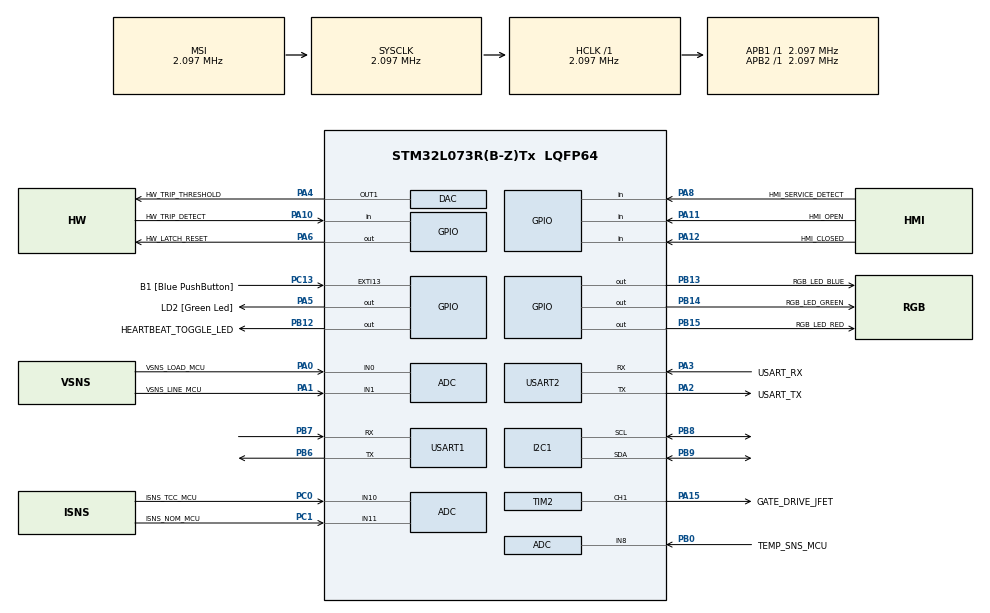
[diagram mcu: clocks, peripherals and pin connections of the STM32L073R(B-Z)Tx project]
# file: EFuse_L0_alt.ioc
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ADC.EOCSelection=ADC_EOC_SEQ_CONV
ADC.SamplingTime=ADC_SAMPLETIME_160CYCLES_5
I2C1.Timing=0x00000608
Mcu.Family=STM32L0
Mcu.Name=STM32L073R(B-Z)Tx
Mcu.Package=LQFP64
PA0.GPIO_Label=VSNS_LOAD_MCU
PA0.Mode=IN0
PA0.Signal=ADC_IN0
PA1.GPIO_Label=VSNS_LINE_MCU
PA1.Mode=IN1
PA1.Signal=ADC_IN1
PA10.GPIO_Label=HW_TRIP_DETECT
PA10.Signal=GPIO_Input
PA11.GPIO_Label=HMI_OPEN
PA11.Signal=GPIO_Input
PA12.GPIO_Label=HMI_CLOSED
PA12.Signal=GPIO_Input
PA13.GPIO_Label=TMS
PA13.Mode=Serial_Wire
PA13.Signal=SYS_SWDIO
PA14.GPIO_Label=TCK
PA14.Mode=Serial_Wire
PA14.Signal=SYS_SWCLK
PA15.GPIO_Label=GATE_DRIVE_JFET
PA15.Signal=S_TIM2_CH1
PA2.GPIO_Label=USART_TX
PA2.Mode=Asynchronous
PA2.Signal=USART2_TX
PA3.GPIO_Label=USART_RX
PA3.Mode=Asynchronous
PA3.Signal=USART2_RX
PA4.GPIO_Label=HW_TRIP_THRESHOLD
PA4.Signal=COMP_DAC1_group
PA5.GPIO_Label=LD2 [Green Led]
PA5.Signal=GPIO_Output
PA6.GPIO_Label=HW_LATCH_RESET
PA6.Signal=GPIO_Output
PA8.GPIO_Label=HMI_SERVICE_DETECT
PA8.Signal=GPIO_Input
PB0.GPIO_Label=TEMP_SNS_MCU
PB0.Mode=IN8
PB0.Signal=ADC_IN8
PB12.GPIO_Label=HEARTBEAT_TOGGLE_LED
PB12.Signal=GPIO_Output
PB13.GPIO_Label=RGB_LED_BLUE
PB13.Signal=GPIO_Output
PB14.GPIO_Label=RGB_LED_GREEN
PB14.Signal=GPIO_Output
PB15.GPIO_Label=RGB_LED_RED
PB15.Signal=GPIO_Output
PB6.Mode=Asynchronous
PB6.Signal=USART1_TX
PB7.Mode=Asynchronous
PB7.Signal=USART1_RX
PB8.Mode=I2C
PB8.Signal=I2C1_SCL
PB9.Mode=I2C
PB9.Signal=I2C1_SDA
PC0.GPIO_Label=ISNS_TCC_MCU
PC0.Mode=IN10
PC0.Signal=ADC_IN10
PC1.GPIO_Label=ISNS_NOM_MCU
PC1.Mode=IN11
PC1.Signal=ADC_IN11
PC13.GPIO_Label=B1 [Blue PushButton]
PC13.GPIO_ModeDefaultEXTI=GPIO_MODE_IT_FALLING
PC13.Signal=GPXTI13
PC14-OSC32_IN.Mode=LSE-External-Oscillator
PC14-OSC32_IN.Signal=RCC_OSC32_IN
PC15-OSC32_OUT.Mode=LSE-External-Oscillator
PC15-OSC32_OUT.Signal=RCC_OSC32_OUT
PH0-OSC_IN.GPIO_Label=MCO
PH0-OSC_IN.Mode=HSE-External-Clock-Source
PH0-OSC_IN.Signal=RCC_OSC_IN
ProjectManager.HeapSize=0x200
ProjectManager.StackSize=0x400
ProjectManager.TargetToolchain=CMake
RCC.AHBFreq_Value=2097000
RCC.APB1Freq_Value=2097000
RCC.APB1TimFreq_Value=2097000
RCC.APB2Freq_Value=2097000
RCC.APB2TimFreq_Value=2097000
RCC.HSE_VALUE=8000000
RCC.HSI16_VALUE=16000000
RCC.HSI48_VALUE=48000000
RCC.HSI_VALUE=16000000
RCC.MSI_VALUE=2097000
RCC.SYSCLKFreq_VALUE=2097000
RCC.VCOOutputFreq_Value=48000000
SH.COMP_DAC1_group.0=DAC_OUT1,DAC_OUT1
SH.S_TIM2_CH1.0=TIM2_CH1,PWM Generation1 CH1
TIM2.Channel-PWM\ Generation1\ CH1=TIM_CHANNEL_1
USART1.VirtualMode-Asynchronous=VM_ASYNC
USART2.VirtualMode-Asynchronous=VM_ASYNC
VP_ADC_TempSens_Input.Mode=IN-TempSens
VP_ADC_Vref_Input.Mode=IN-Vrefint
board=NUCLEO-L073RZ

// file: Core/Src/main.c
/* USER CODE BEGIN Header */
/**
 ******************************************************************************
 * @file           : main.c
 * @brief          : Main program body
 ******************************************************************************
 * @attention
 *
 * Copyright (c) 2025 STMicroelectronics.
 * All rights reserved.
 *
 * This software is licensed under terms that can be found in the LICENSE file
 * in the root directory of this software component.
 * If no LICENSE file comes with this software, it is provided AS-IS.
 *
 ******************************************************************************
 */
/* USER CODE END Header */
#include "main.h"

/* USER CODE BEGIN Includes */
#include <stdio.h>
#include <string.h>
#include "scheduler.h"
/* USER CODE END Includes */

ADC_HandleTypeDef hadc;

DAC_HandleTypeDef hdac;

I2C_HandleTypeDef hi2c1;

TIM_HandleTypeDef htim2;

UART_HandleTypeDef huart1;
UART_HandleTypeDef huart2;

void SystemClock_Config(void);
static void MX_GPIO_Init(void);
static void MX_ADC_Init(void);
static void MX_DAC_Init(void);
static void MX_I2C1_Init(void);
static void MX_TIM2_Init(void);
static void MX_USART1_UART_Init(void);
static void MX_USART2_UART_Init(void);

/* USER CODE BEGIN 0 */
int __io_putchar(int ch)
{
  HAL_UART_Transmit(&huart2, (uint8_t *)&ch, 1, HAL_MAX_DELAY);
  return ch;
}

/* USER CODE END 0 */

int main(void)
{

  /* MCU Configuration--------------------------------------------------------*/

  /* Reset of all peripherals, Initializes the Flash interface and the Systick. */
  HAL_Init();

  /* Configure the system clock */
  SystemClock_Config();

  /* USER CODE BEGIN SysInit */
  SystemCoreClockUpdate();
  SysTick_Config(SystemCoreClock / 1000);
  /* USER CODE END SysInit */

  /* Initialize all configured peripherals */
  MX_GPIO_Init();
  MX_ADC_Init();
  MX_DAC_Init();
  MX_I2C1_Init();
  MX_TIM2_Init();
  MX_USART1_UART_Init();
  MX_USART2_UART_Init();
  /* USER CODE BEGIN 2 */

  Comm_Logf("-I- Efuse Start\r\n");
  // EEPROM_ClearAll();
  EEPROM_WriteBannerRaw(EEPROM_BANNER_TEXT);
  scheduler_run();

  /* USER CODE END 2 */

  /* Infinite loop */
  while (1)
  {

  }
}

void SystemClock_Config(void)
{
  RCC_OscInitTypeDef RCC_OscInitStruct = {0};
  RCC_ClkInitTypeDef RCC_ClkInitStruct = {0};
  RCC_PeriphCLKInitTypeDef PeriphClkInit = {0};

  /** Configure the main internal regulator output voltage
   */
  __HAL_PWR_VOLTAGESCALING_CONFIG(PWR_REGULATOR_VOLTAGE_SCALE1);

  /** Initializes the RCC Oscillators according to the specified parameters
   * in the RCC_OscInitTypeDef structure.
   */
  RCC_OscInitStruct.OscillatorType = RCC_OSCILLATORTYPE_MSI;
  RCC_OscInitStruct.MSIState = RCC_MSI_ON;
  RCC_OscInitStruct.MSICalibrationValue = 0;
  RCC_OscInitStruct.MSIClockRange = RCC_MSIRANGE_5;
  RCC_OscInitStruct.PLL.PLLState = RCC_PLL_NONE;
  if (HAL_RCC_OscConfig(&RCC_OscInitStruct) != HAL_OK)
  {
    Error_Handler();
  }

  /** Initializes the CPU, AHB and APB buses clocks
   */
  RCC_ClkInitStruct.ClockType = RCC_CLOCKTYPE_HCLK | RCC_CLOCKTYPE_SYSCLK | RCC_CLOCKTYPE_PCLK1 | RCC_CLOCKTYPE_PCLK2;
  RCC_ClkInitStruct.SYSCLKSource = RCC_SYSCLKSOURCE_MSI;
  RCC_ClkInitStruct.AHBCLKDivider = RCC_SYSCLK_DIV1;
  RCC_ClkInitStruct.APB1CLKDivider = RCC_HCLK_DIV1;
  RCC_ClkInitStruct.APB2CLKDivider = RCC_HCLK_DIV1;

  if (HAL_RCC_ClockConfig(&RCC_ClkInitStruct, FLASH_LATENCY_0) != HAL_OK)
  {
    Error_Handler();
  }
  PeriphClkInit.PeriphClockSelection = RCC_PERIPHCLK_USART1 | RCC_PERIPHCLK_USART2 | RCC_PERIPHCLK_I2C1;
  PeriphClkInit.Usart1ClockSelection = RCC_USART1CLKSOURCE_PCLK2;
  PeriphClkInit.Usart2ClockSelection = RCC_USART2CLKSOURCE_PCLK1;
  PeriphClkInit.I2c1ClockSelection = RCC_I2C1CLKSOURCE_PCLK1;
  if (HAL_RCCEx_PeriphCLKConfig(&PeriphClkInit) != HAL_OK)
  {
    Error_Handler();
  }
}

static void MX_ADC_Init(void)
{

  ADC_ChannelConfTypeDef sConfig = {0};

  /** Configure the global features of the ADC (Clock, Resolution, Data Alignment and number of conversion)
   */
  hadc.Instance = ADC1;
  hadc.Init.OversamplingMode = DISABLE;
  hadc.Init.ClockPrescaler = ADC_CLOCK_SYNC_PCLK_DIV1;
  hadc.Init.Resolution = ADC_RESOLUTION_12B;
  hadc.Init.SamplingTime = ADC_SAMPLETIME_160CYCLES_5;
  hadc.Init.ScanConvMode = ADC_SCAN_DIRECTION_FORWARD;
  hadc.Init.DataAlign = ADC_DATAALIGN_RIGHT;
  hadc.Init.ContinuousConvMode = DISABLE;
  hadc.Init.DiscontinuousConvMode = DISABLE;
  hadc.Init.ExternalTrigConvEdge = ADC_EXTERNALTRIGCONVEDGE_NONE;
  hadc.Init.ExternalTrigConv = ADC_SOFTWARE_START;
  hadc.Init.DMAContinuousRequests = DISABLE;
  hadc.Init.EOCSelection = ADC_EOC_SINGLE_CONV;
  hadc.Init.Overrun = ADC_OVR_DATA_PRESERVED;
  hadc.Init.LowPowerAutoWait = DISABLE;
  hadc.Init.LowPowerFrequencyMode = ENABLE;
  hadc.Init.LowPowerAutoPowerOff = DISABLE;
  if (HAL_ADC_Init(&hadc) != HAL_OK)
  {
    Error_Handler();
  }

  /** Configure for the selected ADC regular channel to be converted.
   */
  sConfig.Channel = ADC_CHANNEL_0;
  sConfig.Rank = ADC_RANK_CHANNEL_NUMBER;
  if (HAL_ADC_ConfigChannel(&hadc, &sConfig) != HAL_OK)
  {
    Error_Handler();
  }

  /** Configure for the selected ADC regular channel to be converted.
   */
  sConfig.Channel = ADC_CHANNEL_1;
  if (HAL_ADC_ConfigChannel(&hadc, &sConfig) != HAL_OK)
  {
    Error_Handler();
  }

  /** Configure for the selected ADC regular channel to be converted.
   */
  sConfig.Channel = ADC_CHANNEL_8;
  if (HAL_ADC_ConfigChannel(&hadc, &sConfig) != HAL_OK)
  {
    Error_Handler();
  }

  /** Configure for the selected ADC regular channel to be converted.
   */
  sConfig.Channel = ADC_CHANNEL_10;
  if (HAL_ADC_ConfigChannel(&hadc, &sConfig) != HAL_OK)
  {
    Error_Handler();
  }

  /** Configure for the selected ADC regular channel to be converted.
   */
  sConfig.Channel = ADC_CHANNEL_11;
  if (HAL_ADC_ConfigChannel(&hadc, &sConfig) != HAL_OK)
  {
    Error_Handler();
  }

  /** Configure for the selected ADC regular channel to be converted.
   */
  sConfig.Channel = ADC_CHANNEL_TEMPSENSOR;
  if (HAL_ADC_ConfigChannel(&hadc, &sConfig) != HAL_OK)
  {
    Error_Handler();
  }

  /** Configure for the selected ADC regular channel to be converted.
   */
  sConfig.Channel = ADC_CHANNEL_VREFINT;
  if (HAL_ADC_ConfigChannel(&hadc, &sConfig) != HAL_OK)
  {
    Error_Handler();
  }
}

static void MX_DAC_Init(void)
{

  DAC_ChannelConfTypeDef sConfig = {0};

  /** DAC Initialization
   */
  hdac.Instance = DAC;
  if (HAL_DAC_Init(&hdac) != HAL_OK)
  {
    Error_Handler();
  }

  /** DAC channel OUT1 config
   */
  sConfig.DAC_Trigger = DAC_TRIGGER_NONE;
  sConfig.DAC_OutputBuffer = DAC_OUTPUTBUFFER_ENABLE;
  if (HAL_DAC_ConfigChannel(&hdac, &sConfig, DAC_CHANNEL_1) != HAL_OK)
  {
    Error_Handler();
  }
}

static void MX_I2C1_Init(void)
{

  hi2c1.Instance = I2C1;
  hi2c1.Init.Timing = 0x00000608;
  hi2c1.Init.OwnAddress1 = 0;
  hi2c1.Init.AddressingMode = I2C_ADDRESSINGMODE_7BIT;
  hi2c1.Init.DualAddressMode = I2C_DUALADDRESS_DISABLE;
  hi2c1.Init.OwnAddress2 = 0;
  hi2c1.Init.OwnAddress2Masks = I2C_OA2_NOMASK;
  hi2c1.Init.GeneralCallMode = I2C_GENERALCALL_DISABLE;
  hi2c1.Init.NoStretchMode = I2C_NOSTRETCH_DISABLE;
  if (HAL_I2C_Init(&hi2c1) != HAL_OK)
  {
    Error_Handler();
  }

  /** Configure Analogue filter
   */
  if (HAL_I2CEx_ConfigAnalogFilter(&hi2c1, I2C_ANALOGFILTER_ENABLE) != HAL_OK)
  {
    Error_Handler();
  }

  /** Configure Digital filter
   */
  if (HAL_I2CEx_ConfigDigitalFilter(&hi2c1, 0) != HAL_OK)
  {
    Error_Handler();
  }
}

static void MX_TIM2_Init(void)
{

  TIM_MasterConfigTypeDef sMasterConfig = {0};
  TIM_OC_InitTypeDef sConfigOC = {0};

  htim2.Instance = TIM2;
  htim2.Init.Prescaler = 0;
  htim2.Init.CounterMode = TIM_COUNTERMODE_UP;
  htim2.Init.Period = 65535;
  htim2.Init.ClockDivision = TIM_CLOCKDIVISION_DIV1;
  htim2.Init.AutoReloadPreload = TIM_AUTORELOAD_PRELOAD_DISABLE;
  if (HAL_TIM_PWM_Init(&htim2) != HAL_OK)
  {
    Error_Handler();
  }
  sMasterConfig.MasterOutputTrigger = TIM_TRGO_RESET;
  sMasterConfig.MasterSlaveMode = TIM_MASTERSLAVEMODE_DISABLE;
  if (HAL_TIMEx_MasterConfigSynchronization(&htim2, &sMasterConfig) != HAL_OK)
  {
    Error_Handler();
  }
  sConfigOC.OCMode = TIM_OCMODE_PWM1;
  sConfigOC.Pulse = 0;
  sConfigOC.OCPolarity = TIM_OCPOLARITY_HIGH;
  sConfigOC.OCFastMode = TIM_OCFAST_DISABLE;
  if (HAL_TIM_PWM_ConfigChannel(&htim2, &sConfigOC, TIM_CHANNEL_1) != HAL_OK)
  {
    Error_Handler();
  }
  HAL_TIM_MspPostInit(&htim2);
}

static void MX_USART1_UART_Init(void)
{

  huart1.Instance = USART1;
  huart1.Init.BaudRate = 115200;
  huart1.Init.WordLength = UART_WORDLENGTH_8B;
  huart1.Init.StopBits = UART_STOPBITS_1;
  huart1.Init.Parity = UART_PARITY_NONE;
  huart1.Init.Mode = UART_MODE_TX_RX;
  huart1.Init.HwFlowCtl = UART_HWCONTROL_NONE;
  huart1.Init.OverSampling = UART_OVERSAMPLING_16;
  huart1.Init.OneBitSampling = UART_ONE_BIT_SAMPLE_DISABLE;
  huart1.AdvancedInit.AdvFeatureInit = UART_ADVFEATURE_NO_INIT;
  if (HAL_UART_Init(&huart1) != HAL_OK)
  {
    Error_Handler();
  }
}

static void MX_USART2_UART_Init(void)
{

  huart2.Instance = USART2;
  huart2.Init.BaudRate = 115200;
  huart2.Init.WordLength = UART_WORDLENGTH_8B;
  huart2.Init.StopBits = UART_STOPBITS_1;
  huart2.Init.Parity = UART_PARITY_NONE;
  huart2.Init.Mode = UART_MODE_TX_RX;
  huart2.Init.HwFlowCtl = UART_HWCONTROL_NONE;
  huart2.Init.OverSampling = UART_OVERSAMPLING_16;
  huart2.Init.OneBitSampling = UART_ONE_BIT_SAMPLE_DISABLE;
  huart2.AdvancedInit.AdvFeatureInit = UART_ADVFEATURE_NO_INIT;
  if (HAL_UART_Init(&huart2) != HAL_OK)
  {
    Error_Handler();
  }
}

static void MX_GPIO_Init(void)
{
  GPIO_InitTypeDef GPIO_InitStruct = {0};

  /* GPIO Ports Clock Enable */
  __HAL_RCC_GPIOC_CLK_ENABLE();
  __HAL_RCC_GPIOH_CLK_ENABLE();
  __HAL_RCC_GPIOA_CLK_ENABLE();
  __HAL_RCC_GPIOB_CLK_ENABLE();

  /*Configure GPIO pin Output Level */
  HAL_GPIO_WritePin(GPIOA, LD2_Pin | HW_LATCH_RESET_Pin, GPIO_PIN_RESET);

  /*Configure GPIO pin Output Level */
  HAL_GPIO_WritePin(GPIOB, HEARTBEAT_TOGGLE_LED_Pin | RGB_LED_BLUE_Pin | RGB_LED_GREEN_Pin | RGB_LED_RED_Pin, GPIO_PIN_RESET);

  /*Configure GPIO pin : B1_Pin */
  GPIO_InitStruct.Pin = B1_Pin;
  GPIO_InitStruct.Mode = GPIO_MODE_IT_FALLING;
  GPIO_InitStruct.Pull = GPIO_NOPULL;
  HAL_GPIO_Init(B1_GPIO_Port, &GPIO_InitStruct);

  /*Configure GPIO pins : LD2_Pin HW_LATCH_RESET_Pin */
  GPIO_InitStruct.Pin = LD2_Pin | HW_LATCH_RESET_Pin;
  GPIO_InitStruct.Mode = GPIO_MODE_OUTPUT_PP;
  GPIO_InitStruct.Pull = GPIO_NOPULL;
  GPIO_InitStruct.Speed = GPIO_SPEED_FREQ_LOW;
  HAL_GPIO_Init(GPIOA, &GPIO_InitStruct);

  /*Configure GPIO pins : HEARTBEAT_TOGGLE_LED_Pin RGB_LED_BLUE_Pin RGB_LED_GREEN_Pin RGB_LED_RED_Pin */
  GPIO_InitStruct.Pin = HEARTBEAT_TOGGLE_LED_Pin | RGB_LED_BLUE_Pin | RGB_LED_GREEN_Pin | RGB_LED_RED_Pin;
  GPIO_InitStruct.Mode = GPIO_MODE_OUTPUT_PP;
  GPIO_InitStruct.Pull = GPIO_NOPULL;
  GPIO_InitStruct.Speed = GPIO_SPEED_FREQ_LOW;
  HAL_GPIO_Init(GPIOB, &GPIO_InitStruct);

  /*Configure GPIO pins : HMI_SERVICE_DETECT_Pin HW_TRIP_DETECT_Pin HMI_OPEN_Pin HMI_CLOSED_Pin */
  GPIO_InitStruct.Pin = HMI_SERVICE_DETECT_Pin | HW_TRIP_DETECT_Pin | HMI_OPEN_Pin | HMI_CLOSED_Pin;
  GPIO_InitStruct.Mode = GPIO_MODE_INPUT;
  GPIO_InitStruct.Pull = GPIO_NOPULL;
  HAL_GPIO_Init(GPIOA, &GPIO_InitStruct);

}

void Error_Handler(void)
{
  __disable_irq();
  while (1)
  {
  }
}
